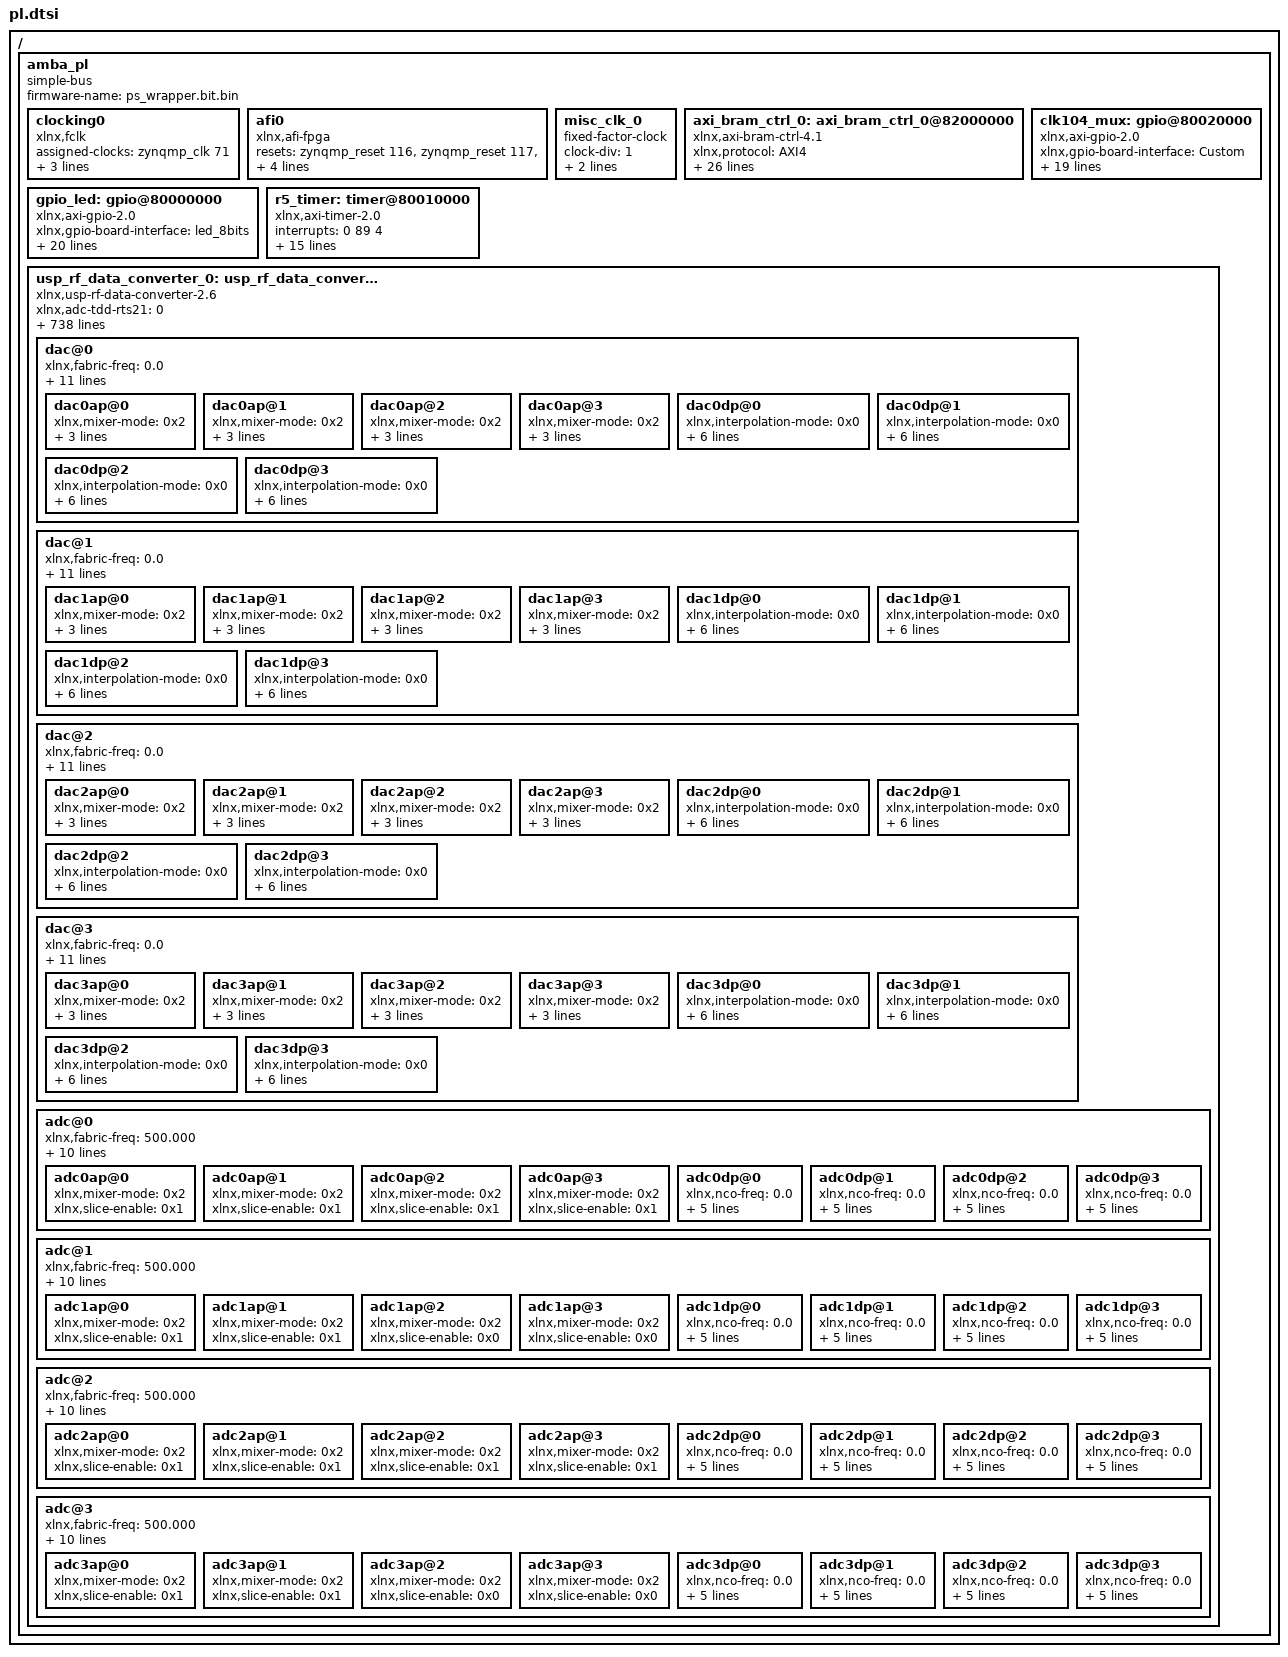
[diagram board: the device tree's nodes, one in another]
/ {
	amba_pl: amba_pl {
		ranges;
		compatible = "simple-bus";
		#address-cells = <2>;
		#size-cells = <2>;
		firmware-name = "ps_wrapper.bit.bin";
		clocking0: clocking0 {
			compatible = "xlnx,fclk";
			status = "okay";
			assigned-clocks = <&zynqmp_clk 71>;
			assigned-clock-rates = <99999001>;
			#clock-cells = <0>;
			clock-output-names = "fabric_clk";
			clocks = <&zynqmp_clk 71>;
		};
		afi0: afi0 {
			status = "okay";
			compatible = "xlnx,afi-fpga";
			resets = <&zynqmp_reset 116>, <&zynqmp_reset 117>, <&zynqmp_reset 118>, <&zynqmp_reset 119>;
			config-afi = < 0 0>, <1 0>, <2 0>, <3 0>, <4 0>, <5 0>, <6 0>, <7 0>, <8 0>, <9 0>, <10 0>, <11 0>, <12 0>, <13 0>, <14 0xa00>, <15 0x000>;
		};
		misc_clk_0: misc_clk_0 {
			clock-div = <1>;
			compatible = "fixed-factor-clock";
			clock-mult = <5>;
			clocks = <&zynqmp_clk 71>;
			#clock-cells = <0>;
		};
		axi_bram_ctrl_0: axi_bram_ctrl_0@82000000 {
			xlnx,protocol = "AXI4";
			xlnx,edk-special = "BRAM_CTRL";
			compatible = "xlnx,axi-bram-ctrl-4.1" , "xlnx,axi-bram-ctrl";
			xlnx,ecc-onoff-reset-value = <0>;
			xlnx,ecc-type = <0>;
			xlnx,rd-cmd-optimization = <0>;
			xlnx,memory-depth = <2048>;
			xlnx,use-ecc = <0>;
			xlnx,fault-inject = <0>;
			xlnx,ip-name = "axi_bram_ctrl";
			reg = <0x0 0x82000000 0x0 0x2000>;
			xlnx,bmg-instance = "EXTERNAL";
			clocks = <&zynqmp_clk 71>;
			xlnx,s-axi-ctrl-addr-width = <32>;
			xlnx,read-latency = <1>;
			xlnx,id-width = <0>;
			xlnx,s-axi-supports-narrow-burst = <0>;
			xlnx,supports-narrow-burst = <0>;
			xlnx,single-port-bram = <1>;
			xlnx,ecc = <0>;
			xlnx,edk-iptype = "PERIPHERAL";
			status = "okay";
			clock-names = "s_axi_aclk";
			xlnx,data-width = <32>;
			xlnx,bram-addr-width = <11>;
			xlnx,bram-inst-mode = "EXTERNAL";
			xlnx,s-axi-ctrl-data-width = <32>;
			xlnx,mem-depth = <2048>;
			xlnx,s-axi-id-width = <1>;
			xlnx,name = "axi_bram_ctrl_0";
		};
		clk104_mux: gpio@80020000 {
			xlnx,gpio-board-interface = "Custom";
			compatible = "xlnx,axi-gpio-2.0" , "xlnx,xps-gpio-1.00.a";
			xlnx,all-outputs = <1>;
			#gpio-cells = <2>;
			xlnx,gpio-width = <2>;
			xlnx,dout-default = <0x0>;
			xlnx,is-dual = <0>;
			xlnx,ip-name = "axi_gpio";
			xlnx,tri-default-2 = <0xffffffff>;
			reg = <0x0 0x80020000 0x0 0x10000>;
			xlnx,all-inputs-2 = <0>;
			clocks = <&zynqmp_clk 71>;
			xlnx,all-outputs-2 = <0>;
			gpio-controller;
			xlnx,interrupt-present = <0>;
			xlnx,gpio2-board-interface = "Custom";
			xlnx,edk-iptype = "PERIPHERAL";
			xlnx,dout-default-2 = <0x0>;
			status = "okay";
			xlnx,gpio2-width = <32>;
			clock-names = "s_axi_aclk";
			xlnx,tri-default = <0xffffffff>;
			xlnx,name = "clk104_mux";
			xlnx,all-inputs = <0>;
		};
		gpio_led: gpio@80000000 {
			xlnx,gpio-board-interface = "led_8bits";
			compatible = "xlnx,axi-gpio-2.0" , "xlnx,xps-gpio-1.00.a";
			xlnx,all-outputs = <1>;
			#gpio-cells = <2>;
			xlnx,gpio-width = <8>;
			xlnx,dout-default = <0x0>;
			xlnx,is-dual = <0>;
			xlnx,ip-name = "axi_gpio";
			xlnx,tri-default-2 = <0xffffffff>;
			reg = <0x0 0x80000000 0x0 0x10000>;
			xlnx,all-inputs-2 = <0>;
			clocks = <&zynqmp_clk 71>;
			xlnx,all-outputs-2 = <0>;
			gpio-controller;
			xlnx,interrupt-present = <0>;
			xlnx,gpio2-board-interface = "Custom";
			xlnx,edk-iptype = "PERIPHERAL";
			xlnx,dout-default-2 = <0x0>;
			status = "okay";
			xlnx,gpio2-width = <32>;
			clock-names = "s_axi_aclk";
			xlnx,use-board-flow;
			xlnx,tri-default = <0xffffffff>;
			xlnx,name = "gpio_led";
			xlnx,all-inputs = <0>;
		};
		r5_timer: timer@80010000 {
			interrupts = < 0 89 4 >;
			compatible = "xlnx,axi-timer-2.0" , "xlnx,xps-timer-1.00.a";
			xlnx,gen1-assert = <1>;
			clock-frequency = <0x5f5dd19>;
			xlnx,trig0-assert = <1>;
			interrupt-parent = <&imux>;
			xlnx,count-width = <32>;
			xlnx,ip-name = "axi_timer";
			xlnx,one-timer-only = <1>;
			reg = <0x0 0x80010000 0x0 0x10000>;
			clocks = <&zynqmp_clk 71>;
			xlnx,gen0-assert = <1>;
			xlnx,mode-64bit = <0>;
			xlnx,edk-iptype = "PERIPHERAL";
			status = "okay";
			xlnx,trig1-assert = <1>;
			clock-names = "s_axi_aclk";
			xlnx,enable-timer2 = <0>;
			interrupt-names = "interrupt";
			xlnx,name = "r5_timer";
		};
		usp_rf_data_converter_0: usp_rf_data_converter@80040000 {
			xlnx,adc-tdd-rts21 = <0>;
			xlnx,adc3-fabric-freq = <500>;
			xlnx,adc-dither32;
			xlnx,dac2-clock-source-mx = <6>;
			xlnx,adc-tdd-rts22 = <0>;
			xlnx,adc-dither33;
			xlnx,mdac-refclk-freq = <6400>;
			xlnx,adc-tdd-rts23 = <0>;
			xlnx,adc-slice31-enable;
			xlnx,adc-nyquist30 = <0>;
			xlnx,adc-nyquist31 = <0>;
			xlnx,dac3-refclk-div = <1>;
			xlnx,axiclk-freq = <100>;
			xlnx,adc-nyquist32 = <0>;
			xlnx,adc-nyquist33 = <0>;
			reg = <0x0 0x80040000 0x0 0x40000>;
			xlnx,adc-tdd-rts30 = <0>;
			xlnx,adc-slice10-enable;
			xlnx,adc2-slices = <2>;
			xlnx,adc-tdd-rts31 = <0>;
			xlnx,adc2-fs-max = <5>;
			xlnx,mdac-fabric-freq = <0>;
			xlnx,dac0-enable = <0>;
			xlnx,adc-tdd-rts32 = <0>;
			xlnx,sysref-master = <0x0>;
			xlnx,adc-tdd-rts33 = <0>;
			xlnx,adc3-link-coupling = <0>;
			xlnx,adc2-refclk-div = <1>;
			xlnx,dac-coarse-mixer-freq00 = <0>;
			xlnx,dac-coarse-mixer-freq01 = <0>;
			xlnx,adc0-slices = <2>;
			xlnx,dac-coarse-mixer-freq02 = <0>;
			xlnx,dac0-sampling-rate = <0x61a800>;
			xlnx,adc0-fs-max = <5>;
			xlnx,adc2-refclk-freq = <4000>;
			xlnx,dac-coarse-mixer-freq03 = <0>;
			xlnx,dac2-outclk-freq = <50>;
			xlnx,adc30-dig-port = <1>;
			xlnx,adc22-dig-port = <1>;
			xlnx,dac-coarse-mixer-freq10 = <0>;
			xlnx,dac3-vco = <8500>;
			xlnx,dac-coarse-mixer-freq11 = <0>;
			xlnx,name = "usp_rf_data_converter_0";
			xlnx,adc2-fabric-freq = <500>;
			xlnx,dac-coarse-mixer-freq12 = <0>;
			xlnx,dac-coarse-mixer-freq13 = <0>;
			xlnx,adc-data-width00 = <8>;
			xlnx,adc-data-width01 = <8>;
			xlnx,adc2-enable = <1>;
			xlnx,adc-data-width02 = <8>;
			xlnx,adc-data-width03 = <8>;
			xlnx,adc0-obs-fabric-freq = <0>;
			xlnx,dac-coarse-mixer-freq20 = <0>;
			xlnx,dac-coarse-mixer-freq21 = <0>;
			xlnx,adc2-obs-fabric-freq = <0>;
			xlnx,dac-coarse-mixer-freq22 = <0>;
			xlnx,dac3-outdiv = <1>;
			xlnx,adc1-band = <0>;
			xlnx,adc3-fbdiv = <24>;
			xlnx,madc-refclk-freq = <2000>;
			xlnx,dac-coarse-mixer-freq23 = <0>;
			xlnx,dac3-link-coupling = <0>;
			xlnx,dac2-band = <0>;
			xlnx,adc-data-width10 = <8>;
			xlnx,adc1-multi-tile-sync;
			xlnx,adc-data-width11 = <8>;
			clock-names = "m0_axis_aclk" , "m1_axis_aclk" , "m2_axis_aclk" , "m3_axis_aclk" , "s_axi_aclk";
			xlnx,adc3-refclk-div = <1>;
			xlnx,adc-data-width12 = <9>;
			xlnx,adc3-multi-tile-sync;
			xlnx,adc-data-width13 = <9>;
			xlnx,madc-decimation-mode00 = <0>;
			xlnx,madc-decimation-mode01 = <0>;
			xlnx,dac-coarse-mixer-freq30 = <0>;
			xlnx,adc1-sampling-rate = <4>;
			xlnx,madc-decimation-mode02 = <0>;
			xlnx,dac-coarse-mixer-freq31 = <0>;
			xlnx,madc-fabric-freq = <0>;
			xlnx,madc-decimation-mode03 = <0>;
			xlnx,dac-coarse-mixer-freq32 = <0>;
			xlnx,adc-slice03-enable;
			xlnx,adc0-enable = <1>;
			xlnx,dac-coarse-mixer-freq33 = <0>;
			xlnx,adc-obs-data-width00 = <8>;
			xlnx,adc-obs-data-width01 = <8>;
			xlnx,adc-data-width20 = <8>;
			xlnx,adc-obs-data-width02 = <8>;
			xlnx,adc-data-width21 = <8>;
			xlnx,mdac-nco-phase00 = <0>;
			xlnx,adc-obs-data-width03 = <8>;
			xlnx,adc1-refclk-freq = <4000>;
			xlnx,adc-data-width22 = <8>;
			xlnx,production-simulation = <0>;
			xlnx,mdac-nco-phase01 = <0>;
			xlnx,dac1-outdiv = <1>;
			xlnx,adc-data-width23 = <8>;
			xlnx,mdac-nco-phase02 = <0>;
			xlnx,adc2-fbdiv = <24>;
			xlnx,mdac-nco-phase03 = <0>;
			xlnx,mdac-data-type00 = <0>;
			xlnx,dac1-outclk-freq = <50>;
			xlnx,use-bram = <1>;
			xlnx,mdac-data-type01 = <0>;
			xlnx,mdac-data-type02 = <0>;
			xlnx,dac0-vco = <8500>;
			xlnx,adc-slice22-enable;
			xlnx,mdac-link-coupling = <0>;
			xlnx,mdac-data-type03 = <0>;
			xlnx,adc-obs-data-width10 = <8>;
			xlnx,disable-bg-cal-en = <1>;
			xlnx,adc-obs-data-width11 = <8>;
			xlnx,adc-coarse-mixer-freq00 = <3>;
			xlnx,adc-data-width30 = <8>;
			xlnx,adc-obs-data-width12 = <8>;
			xlnx,adc1-fabric-freq = <500>;
			xlnx,adc-coarse-mixer-freq01 = <3>;
			xlnx,adc-data-width31 = <8>;
			xlnx,adc-obs-data-width13 = <8>;
			xlnx,adc-coarse-mixer-freq02 = <3>;
			xlnx,adc-data-width32 = <9>;
			xlnx,dac-nyquist00 = <0>;
			xlnx,dac-mode00 = <0>;
			xlnx,adc-slice01-enable;
			xlnx,adc-calopt-mode00 = <1>;
			xlnx,adc-coarse-mixer-freq03 = <3>;
			xlnx,adc-data-width33 = <9>;
			xlnx,dac-nyquist01 = <0>;
			xlnx,dac-nco-phase00 = <0>;
			xlnx,dac-mode01 = <0>;
			xlnx,dac3-fbdiv = <10>;
			xlnx,adc-calopt-mode01 = <1>;
			xlnx,dac-nyquist02 = <0>;
			xlnx,dac-nco-phase01 = <0>;
			xlnx,dac-mode02 = <0>;
			xlnx,adc-calopt-mode02 = <1>;
			xlnx,silicon-revision = <1>;
			xlnx,dac-nyquist03 = <0>;
			xlnx,dac-nco-phase02 = <0>;
			xlnx,dac-mode03 = <0>;
			xlnx,dac0-interpolation = <0>;
			xlnx,adc11-dig-port = <0>;
			xlnx,adc-calopt-mode03 = <1>;
			xlnx,dac-nco-phase03 = <0>;
			xlnx,dac-data-type00 = <0>;
			xlnx,adc03-dig-port = <0>;
			xlnx,adc1-vco = <12000>;
			xlnx,dac-tdd-rts00 = <0>;
			xlnx,dac-data-type01 = <0>;
			xlnx,adc-obs-data-width20 = <8>;
			xlnx,dac-tdd-rts01 = <0>;
			xlnx,dac-data-type02 = <0>;
			xlnx,adc-obs-data-width21 = <8>;
			xlnx,adc-nco-freq00 = <0>;
			xlnx,adc-coarse-mixer-freq10 = <3>;
			xlnx,dac-tdd-rts02 = <0>;
			xlnx,dac-data-type03 = <0>;
			xlnx,adc-obs-data-width22 = <8>;
			xlnx,adc-nco-freq01 = <0>;
			xlnx,adc1-fbdiv = <24>;
			xlnx,adc-coarse-mixer-freq11 = <3>;
			xlnx,dac-tdd-rts03 = <0>;
			xlnx,dac1-sampling-rate = <0x61a800>;
			xlnx,adc-obs-data-width23 = <8>;
			xlnx,adc-nco-freq02 = <0>;
			xlnx,adc-coarse-mixer-freq12 = <0>;
			xlnx,dac-nyquist10 = <0>;
			xlnx,dac-mode10 = <0>;
			xlnx,dac1-vop = <20>;
			xlnx,adc-slice20-enable;
			xlnx,adc-nco-freq03 = <0>;
			xlnx,adc-calopt-mode10 = <1>;
			xlnx,adc-coarse-mixer-freq13 = <0>;
			param-list = [ 00 00 00 00 00 00 04 80 00 00 00 00 01 00 00 00 00 00 00 00 00 00 00 00 01 00 00 00 01 00 00 00 02 00 00 00 01 00 00 00 00 00 00 00 00 00 00 00 9a 99 99 99 99 99 19 40 00 00 00 00 00 00 b9 40 00 00 00 00 00 00 00 00 0a 00 00 00 01 00 00 00 01 00 00 00 00 00 00 00 00 00 00 00 00 00 24 40 02 00 00 00 00 00 00 00 00 00 00 00 00 00 00 00 02 00 00 00 00 00 00 00 00 00 00 00 00 00 00 00 02 00 00 00 00 00 00 00 00 00 00 00 00 00 00 00 02 00 00 00 00 00 00 00 00 00 00 00 00 00 00 00 02 00 00 00 00 00 00 00 00 00 00 00 10 00 00 00 00 00 00 00 00 00 00 00 00 00 00 00 03 00 00 00 00 00 00 00 00 00 00 00 00 00 00 00 10 00 00 00 00 00 00 00 00 00 00 00 00 00 00 00 03 00 00 00 00 00 00 00 00 00 00 00 00 00 00 00 10 00 00 00 00 00 00 00 00 00 00 00 00 00 00 00 03 00 00 00 00 00 00 00 00 00 00 00 00 00 00 00 10 00 00 00 00 00 00 00 00 00 00 00 00 00 00 00 03 00 00 00 00 00 00 00 00 00 00 00 00 00 00 00 00 00 00 00 9a 99 99 99 99 99 19 40 00 00 00 00 00 00 b9 40 00 00 00 00 00 00 00 00 0a 00 00 00 01 00 00 00 01 00 00 00 00 00 00 00 00 00 00 00 00 00 24 40 02 00 00 00 00 00 00 00 00 00 00 00 00 00 00 00 02 00 00 00 00 00 00 00 00 00 00 00 00 00 00 00 02 00 00 00 00 00 00 00 00 00 00 00 00 00 00 00 02 00 00 00 00 00 00 00 00 00 00 00 00 00 00 00 02 00 00 00 00 00 00 00 00 00 00 00 10 00 00 00 00 00 00 00 00 00 00 00 00 00 00 00 03 00 00 00 00 00 00 00 00 00 00 00 00 00 00 00 10 00 00 00 00 00 00 00 00 00 00 00 00 00 00 00 03 00 00 00 00 00 00 00 00 00 00 00 00 00 00 00 10 00 00 00 00 00 00 00 00 00 00 00 00 00 00 00 03 00 00 00 00 00 00 00 00 00 00 00 00 00 00 00 10 00 00 00 00 00 00 00 00 00 00 00 00 00 00 00 03 00 00 00 00 00 00 00 00 00 00 00 00 00 00 00 00 00 00 00 9a 99 99 99 99 99 19 40 00 00 00 00 00 00 b9 40 00 00 00 00 00 00 00 00 0a 00 00 00 01 00 00 00 01 00 00 00 00 00 00 00 00 00 00 00 00 00 24 40 02 00 00 00 00 00 00 00 00 00 00 00 00 00 00 00 02 00 00 00 00 00 00 00 00 00 00 00 00 00 00 00 02 00 00 00 00 00 00 00 00 00 00 00 00 00 00 00 02 00 00 00 00 00 00 00 00 00 00 00 00 00 00 00 02 00 00 00 00 00 00 00 00 00 00 00 10 00 00 00 00 00 00 00 00 00 00 00 00 00 00 00 03 00 00 00 00 00 00 00 00 00 00 00 00 00 00 00 10 00 00 00 00 00 00 00 00 00 00 00 00 00 00 00 03 00 00 00 00 00 00 00 00 00 00 00 00 00 00 00 10 00 00 00 00 00 00 00 00 00 00 00 00 00 00 00 03 00 00 00 00 00 00 00 00 00 00 00 00 00 00 00 10 00 00 00 00 00 00 00 00 00 00 00 00 00 00 00 03 00 00 00 00 00 00 00 00 00 00 00 00 00 00 00 00 00 00 00 9a 99 99 99 99 99 19 40 00 00 00 00 00 00 b9 40 00 00 00 00 00 00 00 00 0a 00 00 00 01 00 00 00 01 00 00 00 00 00 00 00 00 00 00 00 00 00 24 40 02 00 00 00 00 00 00 00 00 00 00 00 00 00 00 00 02 00 00 00 00 00 00 00 00 00 00 00 00 00 00 00 02 00 00 00 00 00 00 00 00 00 00 00 00 00 00 00 02 00 00 00 00 00 00 00 00 00 00 00 00 00 00 00 02 00 00 00 00 00 00 00 00 00 00 00 10 00 00 00 00 00 00 00 00 00 00 00 00 00 00 00 03 00 00 00 00 00 00 00 00 00 00 00 00 00 00 00 10 00 00 00 00 00 00 00 00 00 00 00 00 00 00 00 03 00 00 00 00 00 00 00 00 00 00 00 00 00 00 00 10 00 00 00 00 00 00 00 00 00 00 00 00 00 00 00 03 00 00 00 00 00 00 00 00 00 00 00 00 00 00 00 10 00 00 00 00 00 00 00 00 00 00 00 00 00 00 00 03 00 00 00 00 00 00 00 00 00 00 00 01 00 00 00 00 00 00 00 00 00 00 00 00 00 10 40 00 00 00 00 00 40 af 40 00 00 00 00 00 40 7f 40 18 00 00 00 01 00 00 00 01 00 00 00 00 00 00 00 00 00 00 00 00 00 14 40 02 00 00 00 01 00 00 00 02 00 00 00 01 00 00 00 02 00 00 00 01 00 00 00 02 00 00 00 01 00 00 00 02 00 00 00 00 00 00 00 08 00 00 00 01 00 00 00 00 00 00 00 01 00 00 00 00 00 00 00 00 00 00 00 00 00 00 00 08 00 00 00 01 00 00 00 00 00 00 00 01 00 00 00 00 00 00 00 00 00 00 00 00 00 00 00 08 00 00 00 01 00 00 00 00 00 00 00 01 00 00 00 00 00 00 00 00 00 00 00 00 00 00 00 08 00 00 00 01 00 00 00 00 00 00 00 01 00 00 00 00 00 00 00 00 00 00 00 01 00 00 00 00 00 00 00 00 00 00 00 00 00 10 40 00 00 00 00 00 40 af 40 00 00 00 00 00 40 7f 40 18 00 00 00 01 00 00 00 01 00 00 00 00 00 00 00 00 00 00 00 00 00 14 40 02 00 00 00 01 00 00 00 02 00 00 00 01 00 00 00 02 00 00 00 00 00 00 00 02 00 00 00 00 00 00 00 02 00 00 00 00 00 00 00 08 00 00 00 01 00 00 00 00 00 00 00 01 00 00 00 00 00 00 00 00 00 00 00 00 00 00 00 08 00 00 00 01 00 00 00 00 00 00 00 01 00 00 00 00 00 00 00 00 00 00 00 00 00 00 00 09 00 00 00 00 00 00 00 00 00 00 00 03 00 00 00 00 00 00 00 00 00 00 00 00 00 00 00 09 00 00 00 00 00 00 00 00 00 00 00 03 00 00 00 00 00 00 00 00 00 00 00 01 00 00 00 00 00 00 00 00 00 00 00 00 00 10 40 00 00 00 00 00 40 af 40 00 00 00 00 00 40 7f 40 18 00 00 00 01 00 00 00 01 00 00 00 00 00 00 00 00 00 00 00 00 00 14 40 02 00 00 00 01 00 00 00 02 00 00 00 01 00 00 00 02 00 00 00 01 00 00 00 02 00 00 00 01 00 00 00 02 00 00 00 00 00 00 00 08 00 00 00 01 00 00 00 00 00 00 00 01 00 00 00 00 00 00 00 00 00 00 00 00 00 00 00 08 00 00 00 01 00 00 00 00 00 00 00 01 00 00 00 00 00 00 00 00 00 00 00 00 00 00 00 08 00 00 00 01 00 00 00 00 00 00 00 01 00 00 00 00 00 00 00 00 00 00 00 00 00 00 00 08 00 00 00 01 00 00 00 00 00 00 00 01 00 00 00 00 00 00 00 00 00 00 00 01 00 00 00 00 00 00 00 00 00 00 00 00 00 10 40 00 00 00 00 00 40 af 40 00 00 00 00 00 40 7f 40 18 00 00 00 01 00 00 00 01 00 00 00 00 00 00 00 00 00 00 00 00 00 14 40 02 00 00 00 01 00 00 00 02 00 00 00 01 00 00 00 02 00 00 00 00 00 00 00 02 00 00 00 00 00 00 00 02 00 00 00 00 00 00 00 08 00 00 00 01 00 00 00 00 00 00 00 01 00 00 00 00 00 00 00 00 00 00 00 00 00 00 00 08 00 00 00 01 00 00 00 00 00 00 00 01 00 00 00 00 00 00 00 00 00 00 00 00 00 00 00 09 00 00 00 00 00 00 00 00 00 00 00 03 00 00 00 00 00 00 00 00 00 00 00 00 00 00 00 09 00 00 00 00 00 00 00 00 00 00 00 03 00 00 00 00 00 00 00 00 00 00 00];
			xlnx,mdac-coarse-mixer-freq00 = <0>;
			xlnx,dac-nyquist11 = <0>;
			xlnx,dac-nco-phase10 = <0>;
			xlnx,dac-mode11 = <0>;
			xlnx,dac-mixer-mode00 = <2>;
			xlnx,adc-calopt-mode11 = <1>;
			xlnx,mdac-coarse-mixer-freq01 = <0>;
			xlnx,dac-nyquist12 = <0>;
			xlnx,dac-nco-phase11 = <0>;
			xlnx,dac-mode12 = <0>;
			xlnx,dac-mixer-mode01 = <2>;
			xlnx,adc-calopt-mode12 = <1>;
			xlnx,mdac-coarse-mixer-freq02 = <0>;
			xlnx,dac-nyquist13 = <0>;
			xlnx,dac-nco-phase12 = <0>;
			xlnx,dac-mode13 = <0>;
			xlnx,dac-mixer-mode02 = <2>;
			xlnx,adc-calopt-mode13 = <1>;
			xlnx,mdac-coarse-mixer-freq03 = <0>;
			xlnx,madc-nyquist00 = <0>;
			xlnx,dac-nco-phase13 = <0>;
			xlnx,dac-mixer-mode03 = <2>;
			xlnx,dac-data-type10 = <0>;
			xlnx,madc-nyquist01 = <0>;
			xlnx,dac-tdd-rts10 = <0>;
			xlnx,dac-data-type11 = <0>;
			xlnx,adc-obs-data-width30 = <8>;
			xlnx,madc-refclk-div = <1>;
			xlnx,madc-nyquist02 = <0>;
			xlnx,madc-mixer-mode00 = <2>;
			xlnx,dac-tdd-rts11 = <0>;
			xlnx,dac-data-type12 = <0>;
			xlnx,adc-obs-data-width31 = <8>;
			xlnx,adc-nco-freq10 = <0>;
			xlnx,adc-coarse-mixer-freq20 = <3>;
			xlnx,madc-nyquist03 = <0>;
			xlnx,madc-mixer-mode01 = <2>;
			xlnx,dac-tdd-rts12 = <0>;
			xlnx,dac-data-type13 = <0>;
			xlnx,dac2-fbdiv = <10>;
			xlnx,adc-obs-data-width32 = <8>;
			xlnx,adc-nco-freq11 = <0>;
			xlnx,adc-coarse-mixer-freq21 = <3>;
			xlnx,madc-mixer-mode02 = <2>;
			xlnx,dac-tdd-rts13 = <0>;
			xlnx,adc-obs-data-width33 = <8>;
			xlnx,adc-nco-freq12 = <0>;
			xlnx,adc3-outdiv = <1>;
			xlnx,adc-coarse-mixer-freq22 = <3>;
			xlnx,madc-tdd-rts00 = <0>;
			xlnx,madc-mixer-mode03 = <2>;
			xlnx,dac-nyquist20 = <0>;
			xlnx,dac-mode20 = <0>;
			xlnx,adc-nco-freq13 = <0>;
			xlnx,adc-calopt-mode20 = <1>;
			xlnx,adc-coarse-mixer-freq23 = <3>;
			xlnx,madc-tdd-rts01 = <0>;
			xlnx,dac-nyquist21 = <0>;
			xlnx,dac-nco-phase20 = <0>;
			xlnx,dac-mode21 = <0>;
			xlnx,dac-mixer-mode10 = <2>;
			xlnx,adc-calopt-mode21 = <1>;
			xlnx,madc-tdd-rts02 = <0>;
			xlnx,dac-nyquist22 = <0>;
			xlnx,dac-nco-phase21 = <0>;
			xlnx,dac-mode22 = <0>;
			xlnx,dac-mixer-mode11 = <2>;
			xlnx,converter-setup = <1>;
			xlnx,adc-calopt-mode22 = <1>;
			xlnx,mdac-band = <0>;
			xlnx,madc-tdd-rts03 = <0>;
			xlnx,dac-nyquist23 = <0>;
			xlnx,dac-nco-phase22 = <0>;
			xlnx,dac-mode23 = <0>;
			xlnx,dac-mixer-mode12 = <2>;
			xlnx,adc0-refclk-freq = <4000>;
			xlnx,adc-calopt-mode23 = <1>;
			xlnx,dac-nco-phase23 = <0>;
			xlnx,dac-mixer-mode13 = <2>;
			xlnx,dac-data-type20 = <0>;
			xlnx,adc0-fbdiv = <24>;
			xlnx,mdac-data-width00 = <16>;
			xlnx,dac-tdd-rts20 = <0>;
			xlnx,dac-data-type21 = <0>;
			xlnx,mdac-data-width01 = <16>;
			xlnx,dac-tdd-rts21 = <0>;
			xlnx,dac-data-type22 = <0>;
			xlnx,dac0-outclk-freq = <50>;
			xlnx,adc-nco-freq20 = <0>;
			xlnx,adc-coarse-mixer-freq30 = <3>;
			xlnx,mdac-data-width02 = <16>;
			xlnx,dac-tdd-rts22 = <0>;
			xlnx,dac-data-type23 = <0>;
			xlnx,dac3-slices = <2>;
			xlnx,adc-nco-freq21 = <0>;
			xlnx,adc-coarse-mixer-freq31 = <3>;
			xlnx,mdac-data-width03 = <16>;
			xlnx,dac-tdd-rts23 = <0>;
			xlnx,dac3-fs-max = <10>;
			xlnx,adc-nco-freq22 = <0>;
			xlnx,adc-coarse-mixer-freq32 = <0>;
			xlnx,dac-nyquist30 = <0>;
			xlnx,dac-mode30 = <0>;
			xlnx,adc-nco-freq23 = <0>;
			xlnx,adc-calopt-mode30 = <1>;
			xlnx,adc-coarse-mixer-freq33 = <0>;
			xlnx,dac-nyquist31 = <0>;
			xlnx,dac-nco-phase30 = <0>;
			xlnx,dac-mode31 = <0>;
			xlnx,dac-mixer-mode20 = <2>;
			status = "okay";
			xlnx,adc-calopt-mode31 = <1>;
			xlnx,dac-nyquist32 = <0>;
			xlnx,dac-nco-phase31 = <0>;
			xlnx,dac-mode32 = <0>;
			xlnx,dac-mixer-mode21 = <2>;
			xlnx,adc0-fabric-freq = <500>;
			xlnx,adc-calopt-mode32 = <1>;
			xlnx,madc-nco-phase00 = <0>;
			xlnx,dac-nyquist33 = <0>;
			xlnx,dac-nco-phase32 = <0>;
			xlnx,dac-nco-freq00 = <0>;
			xlnx,dac-mode33 = <0>;
			xlnx,dac-mixer-mode22 = <2>;
			xlnx,adc-calopt-mode33 = <1>;
			xlnx,madc-nco-phase01 = <0>;
			xlnx,dac-nco-phase33 = <0>;
			xlnx,dac-nco-freq01 = <0>;
			xlnx,dac-mixer-type00 = <3>;
			xlnx,dac-mixer-mode23 = <2>;
			xlnx,dac-data-type30 = <0>;
			xlnx,dac1-fbdiv = <10>;
			xlnx,adc1-outdiv = <1>;
			xlnx,madc-nco-phase02 = <0>;
			xlnx,madc-dither00;
			xlnx,dac-tdd-rts30 = <0>;
			xlnx,dac-nco-freq02 = <0>;
			xlnx,dac-mixer-type01 = <3>;
			xlnx,dac-data-type31 = <0>;
			xlnx,dac0-clock-dist = <0>;
			xlnx,adc3-clock-source = <1>;
			xlnx,madc-nco-phase03 = <0>;
			xlnx,madc-dither01;
			xlnx,madc-data-type00 = <0>;
			xlnx,dac-tdd-rts31 = <0>;
			xlnx,dac-nco-freq03 = <0>;
			xlnx,dac-mixer-type02 = <3>;
			xlnx,dac-data-type32 = <0>;
			xlnx,adc-nco-freq30 = <0>;
			xlnx,adc2-sampling-rate = <4>;
			xlnx,mdac-interpolation-mode00 = <0>;
			xlnx,madc-dither02;
			xlnx,madc-data-type01 = <0>;
			xlnx,dac-tdd-rts32 = <0>;
			xlnx,dac-mixer-type03 = <3>;
			xlnx,dac-data-type33 = <0>;
			xlnx,adc-nco-freq31 = <0>;
			xlnx,mdac-interpolation-mode01 = <0>;
			xlnx,madc-dither03;
			xlnx,madc-data-type02 = <0>;
			xlnx,dac-tdd-rts33 = <0>;
			xlnx,adc-nco-freq32 = <0>;
			xlnx,adc3-outclk-freq = <0x1dcd650>;
			xlnx,mdac-interpolation-mode02 = <0>;
			xlnx,madc-sampling-rate = <2>;
			xlnx,madc-mixer-type00 = <3>;
			xlnx,madc-data-type03 = <0>;
			xlnx,dac-output-current = <0>;
			xlnx,adc-nco-freq33 = <0>;
			xlnx,mdac-interpolation-mode03 = <0>;
			xlnx,madc-mixer-type01 = <3>;
			xlnx,dac-mixer-mode30 = <2>;
			xlnx,adc31-dig-port = <0>;
			xlnx,madc-mixer-type02 = <3>;
			xlnx,pl-clock-freq = <125>;
			xlnx,dac-mixer-mode31 = <2>;
			xlnx,adc23-dig-port = <0>;
			xlnx,mdac-refclk-div = <1>;
			xlnx,madc-mixer-type03 = <3>;
			xlnx,dac-nco-freq10 = <0>;
			xlnx,dac-mixer-mode32 = <2>;
			xlnx,dac1-slices = <2>;
			xlnx,adc0-clock-source-mx = <0>;
			xlnx,mdac-decoder-mode00 = <0>;
			xlnx,dac-nco-freq11 = <0>;
			xlnx,dac-mixer-type10 = <3>;
			xlnx,dac-mixer-mode33 = <2>;
			xlnx,dac1-fs-max = <10>;
			xlnx,mdac-decoder-mode01 = <0>;
			xlnx,dac-nco-freq12 = <0>;
			xlnx,dac-mixer-type11 = <3>;
			xlnx,adc-nco-phase00 = <0>;
			xlnx,adc00-dig-port = <1>;
			xlnx,adc2-clock-source-mx = <2>;
			xlnx,mdac-decoder-mode02 = <0>;
			xlnx,edk-iptype = "PERIPHERAL";
			xlnx,dac-nco-freq13 = <0>;
			xlnx,dac-mixer-type12 = <3>;
			xlnx,adc-nco-phase01 = <0>;
			xlnx,mdac-decoder-mode03 = <0>;
			xlnx,dac-mixer-type13 = <3>;
			xlnx,adc-nco-phase02 = <0>;
			xlnx,adc-nco-phase03 = <0>;
			xlnx,adc-data-type00 = <0>;
			xlnx,mdac-outclk-freq = <50>;
			xlnx,adc-data-type01 = <0>;
			xlnx,dac0-fbdiv = <10>;
			xlnx,adc-data-type02 = <0>;
			xlnx,adc-data-type03 = <0>;
			xlnx,dac-nco-freq20 = <0>;
			xlnx,adc0-decimation = <1>;
			xlnx,dac-nco-freq21 = <0>;
			xlnx,dac-mixer-type20 = <3>;
			xlnx,madc-coarse-mixer-freq00 = <0>;
			xlnx,dac-nco-freq22 = <0>;
			xlnx,dac-mixer-type21 = <3>;
			xlnx,adc-nco-phase10 = <0>;
			xlnx,madc-coarse-mixer-freq01 = <0>;
			xlnx,dac-nco-freq23 = <0>;
			xlnx,dac-mixer-type22 = <3>;
			xlnx,adc-nco-phase11 = <0>;
			xlnx,madc-coarse-mixer-freq02 = <0>;
			xlnx,dac-mixer-type23 = <3>;
			xlnx,dac1-interpolation = <0>;
			xlnx,adc-nco-phase12 = <0>;
			xlnx,madc-coarse-mixer-freq03 = <0>;
			xlnx,dac3-enable = <0>;
			xlnx,adc-nco-phase13 = <0>;
			xlnx,adc-data-type10 = <0>;
			xlnx,adc-data-type11 = <0>;
			xlnx,adc2-clock-source = <1>;
			xlnx,adc-data-type12 = <0>;
			xlnx,adc-data-type13 = <0>;
			xlnx,preset = "None";
			xlnx,vnc-include-ois-change;
			xlnx,dac-nco-freq30 = <0>;
			xlnx,dac2-sampling-rate = <0x61a800>;
			xlnx,dac1-clock-dist = <0>;
			xlnx,dac-nco-freq31 = <0>;
			xlnx,dac-mixer-type30 = <3>;
			xlnx,dac-nco-freq32 = <0>;
			xlnx,dac-mixer-type31 = <3>;
			xlnx,adc-nco-phase20 = <0>;
			xlnx,adc3-band = <0>;
			xlnx,dac-nco-freq33 = <0>;
			xlnx,dac-mixer-type32 = <3>;
			xlnx,adc-nco-phase21 = <0>;
			xlnx,mdac-vop = <20>;
			xlnx,dac-mixer-type33 = <3>;
			xlnx,dac2-vco = <8500>;
			xlnx,adc-nco-phase22 = <0>;
			xlnx,adc-nco-phase23 = <0>;
			xlnx,adc-data-type20 = <0>;
			xlnx,madc-enable = <0>;
			xlnx,adc0-link-coupling = <0>;
			xlnx,adc-data-type21 = <0>;
			xlnx,dac1-clock-source-mx = <5>;
			xlnx,adc0-band = <0>;
			xlnx,adc-data-type22 = <0>;
			xlnx,dac1-band = <0>;
			xlnx,adc-slice11-enable;
			xlnx,adc3-slices = <2>;
			xlnx,adc-data-type23 = <0>;
			xlnx,dac3-clock-source-mx = <7>;
			xlnx,adc2-outclk-freq = <0x1dcd650>;
			xlnx,adc3-fs-max = <5>;
			xlnx,dac1-enable = <0>;
			xlnx,adc-nco-phase30 = <0>;
			xlnx,dac-interpolation-mode00 = <0>;
			xlnx,adc-nco-phase31 = <0>;
			xlnx,dac-interpolation-mode01 = <0>;
			xlnx,adc-nco-phase32 = <0>;
			xlnx,adc3-vco = <12000>;
			xlnx,dac-interpolation-mode02 = <0>;
			xlnx,adc-nco-phase33 = <0>;
			xlnx,adc-data-type30 = <0>;
			xlnx,dac-interpolation-mode03 = <0>;
			xlnx,adc0-clock-dist = <0>;
			xlnx,adc-data-type31 = <0>;
			xlnx,adc1-decimation = <1>;
			xlnx,adc-data-type32 = <0>;
			xlnx,adc-slice30-enable;
			xlnx,adc-data-type33 = <0>;
			xlnx,adc-decimation-mode00 = <1>;
			xlnx,dac3-vop = <20>;
			xlnx,adc20-dig-port = <1>;
			xlnx,adc-decimation-mode01 = <1>;
			xlnx,adc12-dig-port = <0>;
			xlnx,adc-decimation-mode02 = <1>;
			xlnx,adc-decimation-mode03 = <1>;
			xlnx,ip-type = <2>;
			xlnx,dac-interpolation-mode10 = <0>;
			xlnx,adc1-clock-source = <1>;
			xlnx,dac-interpolation-mode11 = <0>;
			xlnx,adc1-slices = <2>;
			xlnx,dac-interpolation-mode12 = <0>;
			xlnx,dac3-refclk-freq = <6400>;
			xlnx,adc1-fs-max = <5>;
			compatible = "xlnx,usp-rf-data-converter-2.6";
			xlnx,dac-interpolation-mode13 = <0>;
			xlnx,dac2-clock-dist = <0>;
			xlnx,adc3-sampling-rate = <4>;
			xlnx,adc-decimation-mode10 = <1>;
			xlnx,adc-decimation-mode11 = <1>;
			xlnx,madc-outclk-freq = <0xee6b28>;
			xlnx,adc-decimation-mode12 = <0>;
			xlnx,adc-decimation-mode13 = <0>;
			xlnx,mdac-enable = <0>;
			xlnx,dac-interpolation-mode20 = <0>;
			xlnx,dac0-link-coupling = <0>;
			xlnx,dac-interpolation-mode21 = <0>;
			xlnx,dac3-fabric-freq = <0>;
			xlnx,high-speed-adc = <1>;
			xlnx,dac-interpolation-mode22 = <0>;
			xlnx,dac-interpolation-mode23 = <0>;
			xlnx,adc-decimation-mode20 = <1>;
			xlnx,adc3-enable = <1>;
			xlnx,adc-decimation-mode21 = <1>;
			xlnx,adc-decimation-mode22 = <1>;
			xlnx,adc-decimation-mode23 = <1>;
			xlnx,dac-interpolation-mode30 = <0>;
			xlnx,dac-interpolation-mode31 = <0>;
			xlnx,adc1-outclk-freq = <0x1dcd650>;
			xlnx,adc1-clock-dist = <1>;
			xlnx,dac-interpolation-mode32 = <0>;
			xlnx,adc2-decimation = <1>;
			xlnx,dac-interpolation-mode33 = <0>;
			xlnx,adc0-vco = <12000>;
			xlnx,mdac-nyquist00 = <0>;
			xlnx,dac2-interpolation = <0>;
			xlnx,adc0-clock-source = <1>;
			xlnx,adc-decimation-mode30 = <1>;
			xlnx,mdac-nyquist01 = <0>;
			xlnx,adc-decimation-mode31 = <1>;
			xlnx,mdac-nyquist02 = <0>;
			xlnx,adc1-obs-fabric-freq = <0>;
			xlnx,adc-decimation-mode32 = <0>;
			xlnx,mdac-nyquist03 = <0>;
			xlnx,dac0-vop = <20>;
			xlnx,adc-decimation-mode33 = <0>;
			xlnx,adc3-obs-fabric-freq = <0>;
			xlnx,mdac-tdd-rts00 = <0>;
			xlnx,dac3-sampling-rate = <0x61a800>;
			xlnx,mdac-tdd-rts01 = <0>;
			xlnx,dac3-clock-dist = <0>;
			xlnx,adc1-enable = <1>;
			xlnx,adc0-multi-tile-sync;
			xlnx,mdac-tdd-rts02 = <0>;
			xlnx,mdac-tdd-rts03 = <0>;
			xlnx,mdac-mode00 = <0>;
			xlnx,adc2-multi-tile-sync;
			xlnx,mdac-mode01 = <0>;
			xlnx,reserved-3 = <110000>;
			xlnx,adc32-dig-port = <0>;
			xlnx,mdac-mode02 = <0>;
			xlnx,dac2-refclk-freq = <6400>;
			xlnx,mdac-mode03 = <0>;
			xlnx,dac2-outdiv = <1>;
			xlnx,adc1-link-coupling = <0>;
			xlnx,adc-mixer-mode00 = <2>;
			xlnx,adc01-dig-port = <0>;
			xlnx,adc-mixer-mode01 = <2>;
			xlnx,adc-slice23-enable;
			xlnx,adc-mixer-mode02 = <2>;
			xlnx,adc-mixer-mode03 = <2>;
			xlnx,tb-dac-fft;
			xlnx,dac2-fabric-freq = <0>;
			xlnx,dac3-clock-source = <7>;
			xlnx,vnc-include-fs2-change;
			xlnx,adc-slice02-enable;
			xlnx,dac-data-width00 = <16>;
			xlnx,dac0-refclk-div = <1>;
			xlnx,adc2-clock-dist = <0>;
			xlnx,dac-decoder-mode00 = <0>;
			xlnx,dac-data-width01 = <16>;
			xlnx,adc-mixer-mode10 = <2>;
			xlnx,adc3-decimation = <1>;
			xlnx,mdac-sampling-rate = <0x61a800>;
			xlnx,dac-decoder-mode01 = <0>;
			xlnx,dac-data-width02 = <16>;
			xlnx,analog-detection = <1>;
			xlnx,adc-mixer-mode11 = <2>;
			xlnx,madc-band = <0>;
			xlnx,dac-decoder-mode02 = <0>;
			xlnx,dac-data-width03 = <16>;
			xlnx,adc-mixer-mode12 = <2>;
			num-insts = <1>;
			xlnx,dac-decoder-mode03 = <0>;
			xlnx,dac0-outdiv = <1>;
			xlnx,adc-mixer-mode13 = <2>;
			xlnx,madc-data-width00 = <8>;
			xlnx,madc-data-width01 = <8>;
			xlnx,sysref-source = <1>;
			xlnx,adc0-outclk-freq = <0x1dcd650>;
			xlnx,madc-data-width02 = <8>;
			xlnx,madc-data-width03 = <8>;
			xlnx,dac-vop-mode = <1>;
			xlnx,adc-slice21-enable;
			xlnx,dac-data-width10 = <16>;
			xlnx,adc-obs-decimation-mode00 = <1>;
			xlnx,dac-decoder-mode10 = <0>;
			xlnx,dac-data-width11 = <16>;
			xlnx,adc-obs-decimation-mode01 = <1>;
			xlnx,adc-mixer-mode20 = <2>;
			xlnx,madc-calopt-mode00 = <1>;
			xlnx,dac-decoder-mode11 = <0>;
			xlnx,dac-data-width12 = <16>;
			xlnx,adc-obs-decimation-mode02 = <0>;
			xlnx,adc-mixer-mode21 = <2>;
			xlnx,ip-name = "usp_rf_data_converter";
			xlnx,madc-calopt-mode01 = <1>;
			xlnx,dac-decoder-mode12 = <0>;
			xlnx,dac-data-width13 = <16>;
			xlnx,adc-obs-decimation-mode03 = <0>;
			xlnx,adc-mixer-mode22 = <2>;
			xlnx,madc-calopt-mode02 = <1>;
			xlnx,dac-decoder-mode13 = <0>;
			xlnx,adc-slice00-enable;
			xlnx,adc-mixer-type00 = <1>;
			xlnx,adc-mixer-mode23 = <2>;
			xlnx,madc-calopt-mode03 = <1>;
			xlnx,dac1-link-coupling = <0>;
			xlnx,adc-mixer-type01 = <1>;
			xlnx,adc-mixer-type02 = <1>;
			xlnx,adc-mixer-type03 = <1>;
			xlnx,dac-data-width20 = <16>;
			xlnx,adc-obs-decimation-mode10 = <1>;
			xlnx,dac-decoder-mode20 = <0>;
			xlnx,dac-data-width21 = <16>;
			xlnx,adc-obs-decimation-mode11 = <1>;
			xlnx,adc-mixer-mode30 = <2>;
			xlnx,dac-decoder-mode21 = <0>;
			xlnx,dac-data-width22 = <16>;
			xlnx,dac1-refclk-freq = <6400>;
			xlnx,adc-obs-decimation-mode12 = <1>;
			xlnx,adc-mixer-mode31 = <2>;
			xlnx,dac-decoder-mode22 = <0>;
			xlnx,dac-data-width23 = <16>;
			xlnx,dac2-clock-source = <6>;
			xlnx,adc-obs-decimation-mode13 = <1>;
			xlnx,adc-mixer-mode32 = <2>;
			xlnx,dac-decoder-mode23 = <0>;
			xlnx,adc-mixer-type10 = <1>;
			xlnx,adc-mixer-mode33 = <2>;
			xlnx,adc-mixer-type11 = <1>;
			xlnx,adc-mixer-type12 = <3>;
			xlnx,adc2-band = <0>;
			xlnx,madc-nco-freq00 = <0>;
			xlnx,dac3-band = <0>;
			xlnx,dac1-refclk-div = <1>;
			xlnx,adc-mixer-type13 = <3>;
			xlnx,adc3-clock-dist = <0>;
			xlnx,madc-nco-freq01 = <0>;
			xlnx,adc21-dig-port = <0>;
			xlnx,madc-nco-freq02 = <0>;
			xlnx,dac-data-width30 = <16>;
			xlnx,adc-obs-decimation-mode20 = <1>;
			xlnx,adc13-dig-port = <0>;
			xlnx,madc-nco-freq03 = <0>;
			xlnx,dac-decoder-mode30 = <0>;
			xlnx,dac-data-width31 = <16>;
			xlnx,dac3-interpolation = <0>;
			xlnx,dac1-fabric-freq = <0>;
			xlnx,adc-obs-decimation-mode21 = <1>;
			xlnx,dac-decoder-mode31 = <0>;
			xlnx,dac-data-width32 = <16>;
			xlnx,adc-obs-decimation-mode22 = <1>;
			xlnx,dac-decoder-mode32 = <0>;
			xlnx,dac-data-width33 = <16>;
			xlnx,dac0-band = <0>;
			xlnx,adc-obs-decimation-mode23 = <1>;
			xlnx,adc2-outdiv = <1>;
			xlnx,dac-decoder-mode33 = <0>;
			xlnx,adc-mixer-type20 = <1>;
			xlnx,ams-factory-var = <0>;
			xlnx,adc-mixer-type21 = <1>;
			xlnx,adc-mixer-type22 = <1>;
			xlnx,dac1-vco = <8500>;
			xlnx,adc-mixer-type23 = <1>;
			xlnx,tb-adc-fft;
			xlnx,adc-obs-decimation-mode30 = <1>;
			xlnx,adc-obs-decimation-mode31 = <1>;
			xlnx,dac2-slices = <2>;
			xlnx,adc-obs-decimation-mode32 = <1>;
			xlnx,rf-analyzer = <0>;
			xlnx,dac2-fs-max = <10>;
			xlnx,adc-obs-decimation-mode33 = <1>;
			xlnx,adc2-link-coupling = <0>;
			xlnx,adc-mixer-type30 = <1>;
			xlnx,adc0-refclk-div = <1>;
			xlnx,adc-mixer-type31 = <1>;
			xlnx,adc-dither00;
			xlnx,madc-link-coupling = <0>;
			xlnx,adc-mixer-type32 = <3>;
			xlnx,adc-dither01;
			xlnx,adc-mixer-type33 = <3>;
			xlnx,adc2-vco = <12000>;
			xlnx,adc-dither02;
			xlnx,dac1-clock-source = <5>;
			xlnx,adc0-outdiv = <1>;
			xlnx,adc-dither03;
			clocks = <&misc_clk_0>, <&misc_clk_0>, <&misc_clk_0>, <&misc_clk_0>, <&zynqmp_clk 71>;
			xlnx,mdac-mixer-mode00 = <2>;
			xlnx,mdac-mixer-mode01 = <2>;
			xlnx,adc-nyquist00 = <0>;
			xlnx,adc1-clock-source-mx = <1>;
			xlnx,mdac-mixer-mode02 = <2>;
			xlnx,adc-nyquist01 = <0>;
			xlnx,mdac-mixer-mode03 = <2>;
			xlnx,dac2-vop = <20>;
			xlnx,adc-nyquist02 = <0>;
			xlnx,adc3-clock-source-mx = <3>;
			xlnx,mdac-nco-freq00 = <0>;
			xlnx,adc-nyquist03 = <0>;
			xlnx,mdac-nco-freq01 = <0>;
			xlnx,dac2-refclk-div = <1>;
			xlnx,adc-dither10;
			xlnx,mdac-nco-freq02 = <0>;
			xlnx,dac0-refclk-freq = <6400>;
			xlnx,adc-tdd-rts00 = <0>;
			xlnx,adc-dither11;
			xlnx,mdac-nco-freq03 = <0>;
			xlnx,dac0-slices = <2>;
			xlnx,adc-tdd-rts01 = <0>;
			xlnx,adc-dither12;
			xlnx,dac0-fs-max = <10>;
			xlnx,adc-tdd-rts02 = <0>;
			xlnx,adc-dither13;
			xlnx,adc-tdd-rts03 = <0>;
			xlnx,adc-nyquist10 = <0>;
			xlnx,adc-nyquist11 = <0>;
			xlnx,adc-nyquist12 = <0>;
			xlnx,adc-nyquist13 = <0>;
			xlnx,dac0-fabric-freq = <0>;
			xlnx,adc-dither20;
			xlnx,adc-tdd-rts10 = <0>;
			xlnx,adc-dither21;
			xlnx,adc-tdd-rts11 = <0>;
			xlnx,adc33-dig-port = <0>;
			xlnx,adc-dither22;
			xlnx,adc-tdd-rts12 = <0>;
			xlnx,adc3-refclk-freq = <4000>;
			xlnx,adc-dither23;
			xlnx,dac2-link-coupling = <0>;
			xlnx,adc-tdd-rts13 = <0>;
			xlnx,calibration-time = <10>;
			xlnx,adc-nyquist20 = <0>;
			xlnx,adc10-dig-port = <1>;
			xlnx,dac3-outclk-freq = <50>;
			xlnx,adc-nyquist21 = <0>;
			xlnx,adc1-refclk-div = <1>;
			xlnx,adc02-dig-port = <1>;
			xlnx,mdac-mixer-type00 = <3>;
			xlnx,dac2-enable = <0>;
			xlnx,adc-nyquist22 = <0>;
			xlnx,mdac-mixer-type01 = <3>;
			xlnx,dac0-clock-source = <4>;
			xlnx,adc-nyquist23 = <0>;
			xlnx,mdac-mixer-type02 = <3>;
			xlnx,adc-dither30;
			xlnx,mdac-mixer-type03 = <3>;
			xlnx,dac0-clock-source-mx = <4>;
			xlnx,component-name = "ps_usp_rf_data_converter_0_0";
			xlnx,adc-tdd-rts20 = <0>;
			xlnx,adc0-sampling-rate = <4>;
			xlnx,adc-dither31;
			dac@0 {
				xlnx,fabric-freq = "0.0";
				xlnx,outdiv = <0x1>;
				xlnx,slices = <0x2>;
				xlnx,pll-enable = <0x0>;
				xlnx,sampling-rate = "6.4";
				xlnx,fs-max = "10.000";
				xlnx,link-coupling = <0x0>;
				xlnx,refclk-freq = "6400.000";
				xlnx,fbdiv = <0xa>;
				xlnx,band = <0x0>;
				xlnx,enable = <0x0>;
				xlnx,refclk-div = <0x1>;
				dac0ap@0 {
					xlnx,mixer-mode = <0x2>;
					xlnx,decoder-mode = <0x0>;
					xlnx,invsinc-ctrl = <0x0>;
					xlnx,slice-enable = <0x0>;
				};
				dac0ap@1 {
					xlnx,mixer-mode = <0x2>;
					xlnx,decoder-mode = <0x0>;
					xlnx,invsinc-ctrl = <0x0>;
					xlnx,slice-enable = <0x0>;
				};
				dac0ap@2 {
					xlnx,mixer-mode = <0x2>;
					xlnx,decoder-mode = <0x0>;
					xlnx,invsinc-ctrl = <0x0>;
					xlnx,slice-enable = <0x0>;
				};
				dac0ap@3 {
					xlnx,mixer-mode = <0x2>;
					xlnx,decoder-mode = <0x0>;
					xlnx,invsinc-ctrl = <0x0>;
					xlnx,slice-enable = <0x0>;
				};
				dac0dp@0 {
					xlnx,interpolation-mode = <0x0>;
					xlnx,nco-freq = "0.0";
					xlnx,data-width = <0x10>;
					xlnx,mixer-type = <0x3>;
					xlnx,adder-enable = <0x0>;
					xlnx,fifo-enable = <0x0>;
					xlnx,data-type = <0x0>;
				};
				dac0dp@1 {
					xlnx,interpolation-mode = <0x0>;
					xlnx,nco-freq = "0.0";
					xlnx,data-width = <0x10>;
					xlnx,mixer-type = <0x3>;
					xlnx,adder-enable = <0x0>;
					xlnx,fifo-enable = <0x0>;
					xlnx,data-type = <0x0>;
				};
				dac0dp@2 {
					xlnx,interpolation-mode = <0x0>;
					xlnx,nco-freq = "0.0";
					xlnx,data-width = <0x10>;
					xlnx,mixer-type = <0x3>;
					xlnx,adder-enable = <0x0>;
					xlnx,fifo-enable = <0x0>;
					xlnx,data-type = <0x0>;
				};
				dac0dp@3 {
					xlnx,interpolation-mode = <0x0>;
					xlnx,nco-freq = "0.0";
					xlnx,data-width = <0x10>;
					xlnx,mixer-type = <0x3>;
					xlnx,adder-enable = <0x0>;
					xlnx,fifo-enable = <0x0>;
					xlnx,data-type = <0x0>;
				};
			};
			dac@1 {
				xlnx,fabric-freq = "0.0";
				xlnx,outdiv = <0x1>;
				xlnx,slices = <0x2>;
				xlnx,pll-enable = <0x0>;
				xlnx,sampling-rate = "6.4";
				xlnx,fs-max = "10.000";
				xlnx,link-coupling = <0x0>;
				xlnx,refclk-freq = "6400.000";
				xlnx,fbdiv = <0xa>;
				xlnx,band = <0x0>;
				xlnx,enable = <0x0>;
				xlnx,refclk-div = <0x1>;
				dac1ap@0 {
					xlnx,mixer-mode = <0x2>;
					xlnx,decoder-mode = <0x0>;
					xlnx,invsinc-ctrl = <0x0>;
					xlnx,slice-enable = <0x0>;
				};
				dac1ap@1 {
					xlnx,mixer-mode = <0x2>;
					xlnx,decoder-mode = <0x0>;
					xlnx,invsinc-ctrl = <0x0>;
					xlnx,slice-enable = <0x0>;
				};
				dac1ap@2 {
					xlnx,mixer-mode = <0x2>;
					xlnx,decoder-mode = <0x0>;
					xlnx,invsinc-ctrl = <0x0>;
					xlnx,slice-enable = <0x0>;
				};
				dac1ap@3 {
					xlnx,mixer-mode = <0x2>;
					xlnx,decoder-mode = <0x0>;
					xlnx,invsinc-ctrl = <0x0>;
					xlnx,slice-enable = <0x0>;
				};
				dac1dp@0 {
					xlnx,interpolation-mode = <0x0>;
					xlnx,nco-freq = "0.0";
					xlnx,data-width = <0x10>;
					xlnx,mixer-type = <0x3>;
					xlnx,adder-enable = <0x0>;
					xlnx,fifo-enable = <0x0>;
					xlnx,data-type = <0x0>;
				};
				dac1dp@1 {
					xlnx,interpolation-mode = <0x0>;
					xlnx,nco-freq = "0.0";
					xlnx,data-width = <0x10>;
					xlnx,mixer-type = <0x3>;
					xlnx,adder-enable = <0x0>;
					xlnx,fifo-enable = <0x0>;
					xlnx,data-type = <0x0>;
				};
				dac1dp@2 {
					xlnx,interpolation-mode = <0x0>;
					xlnx,nco-freq = "0.0";
					xlnx,data-width = <0x10>;
					xlnx,mixer-type = <0x3>;
					xlnx,adder-enable = <0x0>;
					xlnx,fifo-enable = <0x0>;
					xlnx,data-type = <0x0>;
				};
				dac1dp@3 {
					xlnx,interpolation-mode = <0x0>;
					xlnx,nco-freq = "0.0";
					xlnx,data-width = <0x10>;
					xlnx,mixer-type = <0x3>;
					xlnx,adder-enable = <0x0>;
					xlnx,fifo-enable = <0x0>;
					xlnx,data-type = <0x0>;
				};
			};
			dac@2 {
				xlnx,fabric-freq = "0.0";
				xlnx,outdiv = <0x1>;
				xlnx,slices = <0x2>;
				xlnx,pll-enable = <0x0>;
				xlnx,sampling-rate = "6.4";
				xlnx,fs-max = "10.000";
				xlnx,link-coupling = <0x0>;
				xlnx,refclk-freq = "6400.000";
				xlnx,fbdiv = <0xa>;
				xlnx,band = <0x0>;
				xlnx,enable = <0x0>;
				xlnx,refclk-div = <0x1>;
				dac2ap@0 {
					xlnx,mixer-mode = <0x2>;
					xlnx,decoder-mode = <0x0>;
					xlnx,invsinc-ctrl = <0x0>;
					xlnx,slice-enable = <0x0>;
				};
				dac2ap@1 {
					xlnx,mixer-mode = <0x2>;
					xlnx,decoder-mode = <0x0>;
					xlnx,invsinc-ctrl = <0x0>;
					xlnx,slice-enable = <0x0>;
				};
				dac2ap@2 {
					xlnx,mixer-mode = <0x2>;
					xlnx,decoder-mode = <0x0>;
					xlnx,invsinc-ctrl = <0x0>;
					xlnx,slice-enable = <0x0>;
				};
				dac2ap@3 {
					xlnx,mixer-mode = <0x2>;
					xlnx,decoder-mode = <0x0>;
					xlnx,invsinc-ctrl = <0x0>;
					xlnx,slice-enable = <0x0>;
				};
				dac2dp@0 {
					xlnx,interpolation-mode = <0x0>;
					xlnx,nco-freq = "0.0";
					xlnx,data-width = <0x10>;
					xlnx,mixer-type = <0x3>;
					xlnx,adder-enable = <0x0>;
					xlnx,fifo-enable = <0x0>;
					xlnx,data-type = <0x0>;
				};
				dac2dp@1 {
					xlnx,interpolation-mode = <0x0>;
					xlnx,nco-freq = "0.0";
					xlnx,data-width = <0x10>;
					xlnx,mixer-type = <0x3>;
					xlnx,adder-enable = <0x0>;
					xlnx,fifo-enable = <0x0>;
					xlnx,data-type = <0x0>;
				};
				dac2dp@2 {
					xlnx,interpolation-mode = <0x0>;
					xlnx,nco-freq = "0.0";
					xlnx,data-width = <0x10>;
					xlnx,mixer-type = <0x3>;
					xlnx,adder-enable = <0x0>;
					xlnx,fifo-enable = <0x0>;
					xlnx,data-type = <0x0>;
				};
				dac2dp@3 {
					xlnx,interpolation-mode = <0x0>;
					xlnx,nco-freq = "0.0";
					xlnx,data-width = <0x10>;
					xlnx,mixer-type = <0x3>;
					xlnx,adder-enable = <0x0>;
					xlnx,fifo-enable = <0x0>;
					xlnx,data-type = <0x0>;
				};
			};
			dac@3 {
				xlnx,fabric-freq = "0.0";
				xlnx,outdiv = <0x1>;
				xlnx,slices = <0x2>;
				xlnx,pll-enable = <0x0>;
				xlnx,sampling-rate = "6.4";
				xlnx,fs-max = "10.000";
				xlnx,link-coupling = <0x0>;
				xlnx,refclk-freq = "6400.000";
				xlnx,fbdiv = <0xa>;
				xlnx,band = <0x0>;
				xlnx,enable = <0x0>;
				xlnx,refclk-div = <0x1>;
				dac3ap@0 {
					xlnx,mixer-mode = <0x2>;
					xlnx,decoder-mode = <0x0>;
					xlnx,invsinc-ctrl = <0x0>;
					xlnx,slice-enable = <0x0>;
				};
				dac3ap@1 {
					xlnx,mixer-mode = <0x2>;
					xlnx,decoder-mode = <0x0>;
					xlnx,invsinc-ctrl = <0x0>;
					xlnx,slice-enable = <0x0>;
				};
				dac3ap@2 {
					xlnx,mixer-mode = <0x2>;
					xlnx,decoder-mode = <0x0>;
					xlnx,invsinc-ctrl = <0x0>;
					xlnx,slice-enable = <0x0>;
				};
				dac3ap@3 {
					xlnx,mixer-mode = <0x2>;
					xlnx,decoder-mode = <0x0>;
					xlnx,invsinc-ctrl = <0x0>;
					xlnx,slice-enable = <0x0>;
				};
				dac3dp@0 {
					xlnx,interpolation-mode = <0x0>;
					xlnx,nco-freq = "0.0";
					xlnx,data-width = <0x10>;
					xlnx,mixer-type = <0x3>;
					xlnx,adder-enable = <0x0>;
					xlnx,fifo-enable = <0x0>;
					xlnx,data-type = <0x0>;
				};
				dac3dp@1 {
					xlnx,interpolation-mode = <0x0>;
					xlnx,nco-freq = "0.0";
					xlnx,data-width = <0x10>;
					xlnx,mixer-type = <0x3>;
					xlnx,adder-enable = <0x0>;
					xlnx,fifo-enable = <0x0>;
					xlnx,data-type = <0x0>;
				};
				dac3dp@2 {
					xlnx,interpolation-mode = <0x0>;
					xlnx,nco-freq = "0.0";
					xlnx,data-width = <0x10>;
					xlnx,mixer-type = <0x3>;
					xlnx,adder-enable = <0x0>;
					xlnx,fifo-enable = <0x0>;
					xlnx,data-type = <0x0>;
				};
				dac3dp@3 {
					xlnx,interpolation-mode = <0x0>;
					xlnx,nco-freq = "0.0";
					xlnx,data-width = <0x10>;
					xlnx,mixer-type = <0x3>;
					xlnx,adder-enable = <0x0>;
					xlnx,fifo-enable = <0x0>;
					xlnx,data-type = <0x0>;
				};
			};
			adc@0 {
				xlnx,fabric-freq = "500.000";
				xlnx,refclk-freq = "4000.000";
				xlnx,slices = <0x2>;
				xlnx,refclk-div = <0x1>;
				xlnx,outdiv = <0x1>;
				xlnx,fbdiv = <0x18>;
				xlnx,enable = <0x1>;
				xlnx,fs-max = "5.000";
				xlnx,sampling-rate = <0x4>;
				xlnx,pll-enable = <0x0>;
				xlnx,band = <0x0>;
				adc0ap@0 {
					xlnx,mixer-mode = <0x2>;
					xlnx,slice-enable = <0x1>;
				};
				adc0ap@1 {
					xlnx,mixer-mode = <0x2>;
					xlnx,slice-enable = <0x1>;
				};
				adc0ap@2 {
					xlnx,mixer-mode = <0x2>;
					xlnx,slice-enable = <0x1>;
				};
				adc0ap@3 {
					xlnx,mixer-mode = <0x2>;
					xlnx,slice-enable = <0x1>;
				};
				adc0dp@0 {
					xlnx,nco-freq = "0.0";
					xlnx,decimation-mode = <0x1>;
					xlnx,data-width = <0x8>;
					xlnx,mixer-type = <0x1>;
					xlnx,fifo-enable = <0x0>;
					xlnx,data-type = <0x0>;
				};
				adc0dp@1 {
					xlnx,nco-freq = "0.0";
					xlnx,decimation-mode = <0x1>;
					xlnx,data-width = <0x8>;
					xlnx,mixer-type = <0x1>;
					xlnx,fifo-enable = <0x0>;
					xlnx,data-type = <0x0>;
				};
				adc0dp@2 {
					xlnx,nco-freq = "0.0";
					xlnx,decimation-mode = <0x1>;
					xlnx,data-width = <0x8>;
					xlnx,mixer-type = <0x1>;
					xlnx,fifo-enable = <0x0>;
					xlnx,data-type = <0x0>;
				};
				adc0dp@3 {
					xlnx,nco-freq = "0.0";
					xlnx,decimation-mode = <0x1>;
					xlnx,data-width = <0x8>;
					xlnx,mixer-type = <0x1>;
					xlnx,fifo-enable = <0x0>;
					xlnx,data-type = <0x0>;
				};
			};
			adc@1 {
				xlnx,fabric-freq = "500.000";
				xlnx,refclk-freq = "4000.000";
				xlnx,slices = <0x2>;
				xlnx,refclk-div = <0x1>;
				xlnx,outdiv = <0x1>;
				xlnx,fbdiv = <0x18>;
				xlnx,enable = <0x1>;
				xlnx,fs-max = "5.000";
				xlnx,sampling-rate = <0x4>;
				xlnx,pll-enable = <0x0>;
				xlnx,band = <0x0>;
				adc1ap@0 {
					xlnx,mixer-mode = <0x2>;
					xlnx,slice-enable = <0x1>;
				};
				adc1ap@1 {
					xlnx,mixer-mode = <0x2>;
					xlnx,slice-enable = <0x1>;
				};
				adc1ap@2 {
					xlnx,mixer-mode = <0x2>;
					xlnx,slice-enable = <0x0>;
				};
				adc1ap@3 {
					xlnx,mixer-mode = <0x2>;
					xlnx,slice-enable = <0x0>;
				};
				adc1dp@0 {
					xlnx,nco-freq = "0.0";
					xlnx,decimation-mode = <0x1>;
					xlnx,data-width = <0x8>;
					xlnx,mixer-type = <0x1>;
					xlnx,fifo-enable = <0x0>;
					xlnx,data-type = <0x0>;
				};
				adc1dp@1 {
					xlnx,nco-freq = "0.0";
					xlnx,decimation-mode = <0x1>;
					xlnx,data-width = <0x8>;
					xlnx,mixer-type = <0x1>;
					xlnx,fifo-enable = <0x0>;
					xlnx,data-type = <0x0>;
				};
				adc1dp@2 {
					xlnx,nco-freq = "0.0";
					xlnx,decimation-mode = <0x0>;
					xlnx,data-width = <0x9>;
					xlnx,mixer-type = <0x3>;
					xlnx,fifo-enable = <0x0>;
					xlnx,data-type = <0x0>;
				};
				adc1dp@3 {
					xlnx,nco-freq = "0.0";
					xlnx,decimation-mode = <0x0>;
					xlnx,data-width = <0x9>;
					xlnx,mixer-type = <0x3>;
					xlnx,fifo-enable = <0x0>;
					xlnx,data-type = <0x0>;
				};
			};
			adc@2 {
				xlnx,fabric-freq = "500.000";
				xlnx,refclk-freq = "4000.000";
				xlnx,slices = <0x2>;
				xlnx,refclk-div = <0x1>;
				xlnx,outdiv = <0x1>;
				xlnx,fbdiv = <0x18>;
				xlnx,enable = <0x1>;
				xlnx,fs-max = "5.000";
				xlnx,sampling-rate = <0x4>;
				xlnx,pll-enable = <0x0>;
				xlnx,band = <0x0>;
				adc2ap@0 {
					xlnx,mixer-mode = <0x2>;
					xlnx,slice-enable = <0x1>;
				};
				adc2ap@1 {
					xlnx,mixer-mode = <0x2>;
					xlnx,slice-enable = <0x1>;
				};
				adc2ap@2 {
					xlnx,mixer-mode = <0x2>;
					xlnx,slice-enable = <0x1>;
				};
				adc2ap@3 {
					xlnx,mixer-mode = <0x2>;
					xlnx,slice-enable = <0x1>;
				};
				adc2dp@0 {
					xlnx,nco-freq = "0.0";
					xlnx,decimation-mode = <0x1>;
					xlnx,data-width = <0x8>;
					xlnx,mixer-type = <0x1>;
					xlnx,fifo-enable = <0x0>;
					xlnx,data-type = <0x0>;
				};
				adc2dp@1 {
					xlnx,nco-freq = "0.0";
					xlnx,decimation-mode = <0x1>;
					xlnx,data-width = <0x8>;
					xlnx,mixer-type = <0x1>;
					xlnx,fifo-enable = <0x0>;
					xlnx,data-type = <0x0>;
				};
				adc2dp@2 {
					xlnx,nco-freq = "0.0";
					xlnx,decimation-mode = <0x1>;
					xlnx,data-width = <0x8>;
					xlnx,mixer-type = <0x1>;
					xlnx,fifo-enable = <0x0>;
					xlnx,data-type = <0x0>;
				};
				adc2dp@3 {
					xlnx,nco-freq = "0.0";
					xlnx,decimation-mode = <0x1>;
					xlnx,data-width = <0x8>;
					xlnx,mixer-type = <0x1>;
					xlnx,fifo-enable = <0x0>;
					xlnx,data-type = <0x0>;
				};
			};
			adc@3 {
				xlnx,fabric-freq = "500.000";
				xlnx,refclk-freq = "4000.000";
				xlnx,slices = <0x2>;
				xlnx,refclk-div = <0x1>;
				xlnx,outdiv = <0x1>;
				xlnx,fbdiv = <0x18>;
				xlnx,enable = <0x1>;
				xlnx,fs-max = "5.000";
				xlnx,sampling-rate = <0x4>;
				xlnx,pll-enable = <0x0>;
				xlnx,band = <0x0>;
				adc3ap@0 {
					xlnx,mixer-mode = <0x2>;
					xlnx,slice-enable = <0x1>;
				};
				adc3ap@1 {
					xlnx,mixer-mode = <0x2>;
					xlnx,slice-enable = <0x1>;
				};
				adc3ap@2 {
					xlnx,mixer-mode = <0x2>;
					xlnx,slice-enable = <0x0>;
				};
				adc3ap@3 {
					xlnx,mixer-mode = <0x2>;
					xlnx,slice-enable = <0x0>;
				};
				adc3dp@0 {
					xlnx,nco-freq = "0.0";
					xlnx,decimation-mode = <0x1>;
					xlnx,data-width = <0x8>;
					xlnx,mixer-type = <0x1>;
					xlnx,fifo-enable = <0x0>;
					xlnx,data-type = <0x0>;
				};
				adc3dp@1 {
					xlnx,nco-freq = "0.0";
					xlnx,decimation-mode = <0x1>;
					xlnx,data-width = <0x8>;
					xlnx,mixer-type = <0x1>;
					xlnx,fifo-enable = <0x0>;
					xlnx,data-type = <0x0>;
				};
				adc3dp@2 {
					xlnx,nco-freq = "0.0";
					xlnx,decimation-mode = <0x0>;
					xlnx,data-width = <0x9>;
					xlnx,mixer-type = <0x3>;
					xlnx,fifo-enable = <0x0>;
					xlnx,data-type = <0x0>;
				};
				adc3dp@3 {
					xlnx,nco-freq = "0.0";
					xlnx,decimation-mode = <0x0>;
					xlnx,data-width = <0x9>;
					xlnx,mixer-type = <0x3>;
					xlnx,fifo-enable = <0x0>;
					xlnx,data-type = <0x0>;
				};
			};
		};
	};
};
